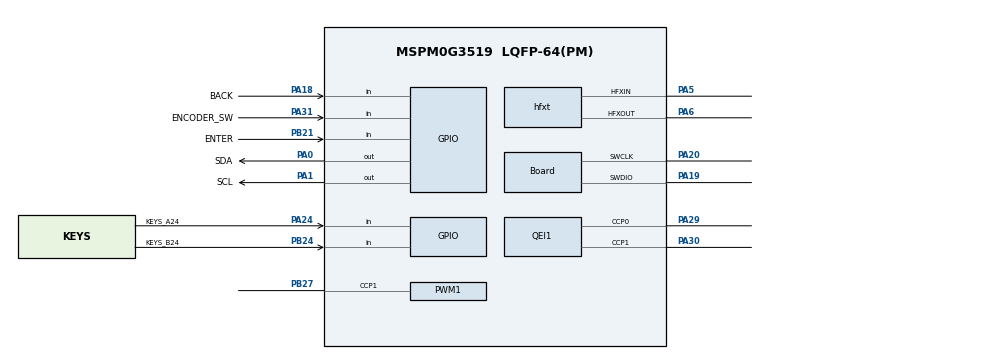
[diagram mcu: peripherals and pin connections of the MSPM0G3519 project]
/**
 * @cliArgs --device "MSPM0G3519" --package "LQFP-64(PM)"
 * @versions {"tool":"1.24.0+4110"}
 */

const GPIO   = scripting.addModule("/ti/driverlib/GPIO", {}, false);
const GPIO1  = GPIO.addInstance();
const GPIO2  = GPIO.addInstance();
const PWM    = scripting.addModule("/ti/driverlib/PWM", {}, false);
const PWM1   = PWM.addInstance();
const PWM2   = PWM.addInstance();
const QEI    = scripting.addModule("/ti/driverlib/QEI", {}, false);
const QEI1   = QEI.addInstance();
const TIMER  = scripting.addModule("/ti/driverlib/TIMER", {}, false);
const TIMER1 = TIMER.addInstance();
const SYSCTL = scripting.addModule("/ti/driverlib/SYSCTL");

/* ---- 80 MHz clock tree ---- */
SYSCTL.forceDefaultClkConfig = true;
SYSCTL.clockTreeEn           = true;
scripting.suppress("For best practices when the CPUCLK is running at 32MHz and above, clear the flash status bit using DL_FlashCTL_executeClearStatus\\(\\) before executing any flash operation\\. Otherwise there may be false positives\\.", SYSCTL);
system.clockTree["UDIV"].divideValue       = 2;
system.clockTree["PLL_QDIV"].multiplyValue = 4;
system.clockTree["EXHFMUX"].inputSelect    = "EXHFMUX_XTAL";
system.clockTree["HSCLKMUX"].inputSelect   = "HSCLKMUX_SYSPLL0";
system.clockTree["SYSPLLMUX"].inputSelect  = "zSYSPLLMUX_HFCLK";
const hfxt = system.clockTree["HFXT"];
hfxt.inputFreq = 40; hfxt.enable = true; hfxt.HFXTStartup = 10; hfxt.HFCLKMonitor = true;
hfxt.peripheral.$assign = "SYSCTL";
hfxt.peripheral.hfxInPin.$assign  = "PA5";
hfxt.peripheral.hfxOutPin.$assign = "PA6";

/* ---- Board: SWD debug ---- */
const Board = scripting.addModule("/ti/driverlib/Board", {}, false);
Board.peripheral.$assign = "DEBUGSS";
Board.peripheral.swclkPin.$assign = "PA20";
Board.peripheral.swdioPin.$assign = "PA19";

/* ---- OLED I2C: PA0=SDA, PA1=SCL (GPIO only; I2C0 init by OLED_driver.c) ---- */
GPIO1.$name = "OLED";
GPIO1.associatedPins.create(2);
GPIO1.associatedPins[0].$name = "SDA";
GPIO1.associatedPins[0].direction    = "OUTPUT";
GPIO1.associatedPins[0].initialValue = "SET";
GPIO1.associatedPins[0].assignedPort = "PORTA";
GPIO1.associatedPins[0].assignedPin  = "0";
GPIO1.associatedPins[0].ioStructure  = "OD";
GPIO1.associatedPins[0].pin.$assign  = "PA0";
GPIO1.associatedPins[1].$name = "SCL";
GPIO1.associatedPins[1].direction    = "OUTPUT";
GPIO1.associatedPins[1].initialValue = "SET";
GPIO1.associatedPins[1].assignedPort = "PORTA";
GPIO1.associatedPins[1].assignedPin  = "1";
GPIO1.associatedPins[1].ioStructure  = "OD";
GPIO1.associatedPins[1].pin.$assign  = "PA1";

/* ---- All 5 buttons in single KEY instance ---- */
GPIO2.$name = "KEY";
GPIO2.associatedPins.create(5);
GPIO2.associatedPins[0].$name = "ENTER";           /* PB21 */
GPIO2.associatedPins[0].direction = "INPUT";
GPIO2.associatedPins[0].internalResistor = "PULL_UP";
GPIO2.associatedPins[0].assignedPort = "PORTB";
GPIO2.associatedPins[0].assignedPin  = "21";
GPIO2.associatedPins[0].pin.$assign = "PB21";
GPIO2.associatedPins[1].$name = "BACK";            /* PA18 */
GPIO2.associatedPins[1].direction = "INPUT";
GPIO2.associatedPins[1].internalResistor = "PULL_DOWN";
GPIO2.associatedPins[1].assignedPort = "PORTA";
GPIO2.associatedPins[1].assignedPin  = "18";
GPIO2.associatedPins[1].pin.$assign = "PA18";
GPIO2.associatedPins[2].$name = "ENCODER_SW";      /* PA31 */
GPIO2.associatedPins[2].direction = "INPUT";
GPIO2.associatedPins[2].internalResistor = "PULL_UP";
GPIO2.associatedPins[2].assignedPort = "PORTA";
GPIO2.associatedPins[2].assignedPin  = "31";
GPIO2.associatedPins[2].pin.$assign = "PA31";
GPIO2.associatedPins[3].$name = "KEYS_A24";        /* PA24 */
GPIO2.associatedPins[3].direction = "INPUT";
GPIO2.associatedPins[3].internalResistor = "PULL_UP";
GPIO2.associatedPins[3].assignedPort = "PORTA";
GPIO2.associatedPins[3].assignedPin  = "24";
GPIO2.associatedPins[3].pin.$assign = "PA24";
GPIO2.associatedPins[4].$name = "KEYS_B24";        /* PB24 */
GPIO2.associatedPins[4].direction = "INPUT";
GPIO2.associatedPins[4].internalResistor = "PULL_UP";
GPIO2.associatedPins[4].assignedPort = "PORTB";
GPIO2.associatedPins[4].assignedPin  = "24";
GPIO2.associatedPins[4].pin.$assign = "PB24";

/* ---- Buzzer PWM: TIMG6 CCP1 on PB27 ---- */
PWM1.$name                          = "BUZZER";
PWM1.pwmMode                        = "EDGE_ALIGN_UP";
PWM1.ccIndex                        = [1];
PWM1.clockPrescale                  = 80;
PWM1.timerCount                     = 1000;
PWM1.timerStartTimer                = false;
PWM1.peripheral.$assign             = "TIMG6";
PWM1.peripheral.ccp1Pin.$assign     = "PB27";
PWM1.PWM_CHANNEL_1.dutyCycle        = 50;

/* ---- Timer tick: TIMA0 5ms (for mid_timer / encoder polling) ---- */
TIMER1.$name                          = "TIMER_TICK";
TIMER1.timerClkDiv                    = 8;
TIMER1.timerClkPrescale               = 10;
TIMER1.timerStartTimer                = true;
TIMER1.timerMode                      = "PERIODIC";
TIMER1.interrupts                     = ["ZERO"];
TIMER1.interruptPriority              = "3";
TIMER1.timerPeriod                    = "5 ms";
TIMER1.peripheral.$assign             = "TIMA0";

/* ---- QEI Encoder: TIMG8 on PA29/PA30 ---- */
QEI1.$name                  = "QEI_ENCODER";
QEI1.peripheral.$assign     = "TIMG8";
QEI1.peripheral.ccp0Pin.$assign = "PA29";
QEI1.peripheral.ccp1Pin.$assign = "PA30";

const ProjectConfig = scripting.addModule("/ti/project_config/ProjectConfig", {}, false);
ProjectConfig.migrationCondition = true;
